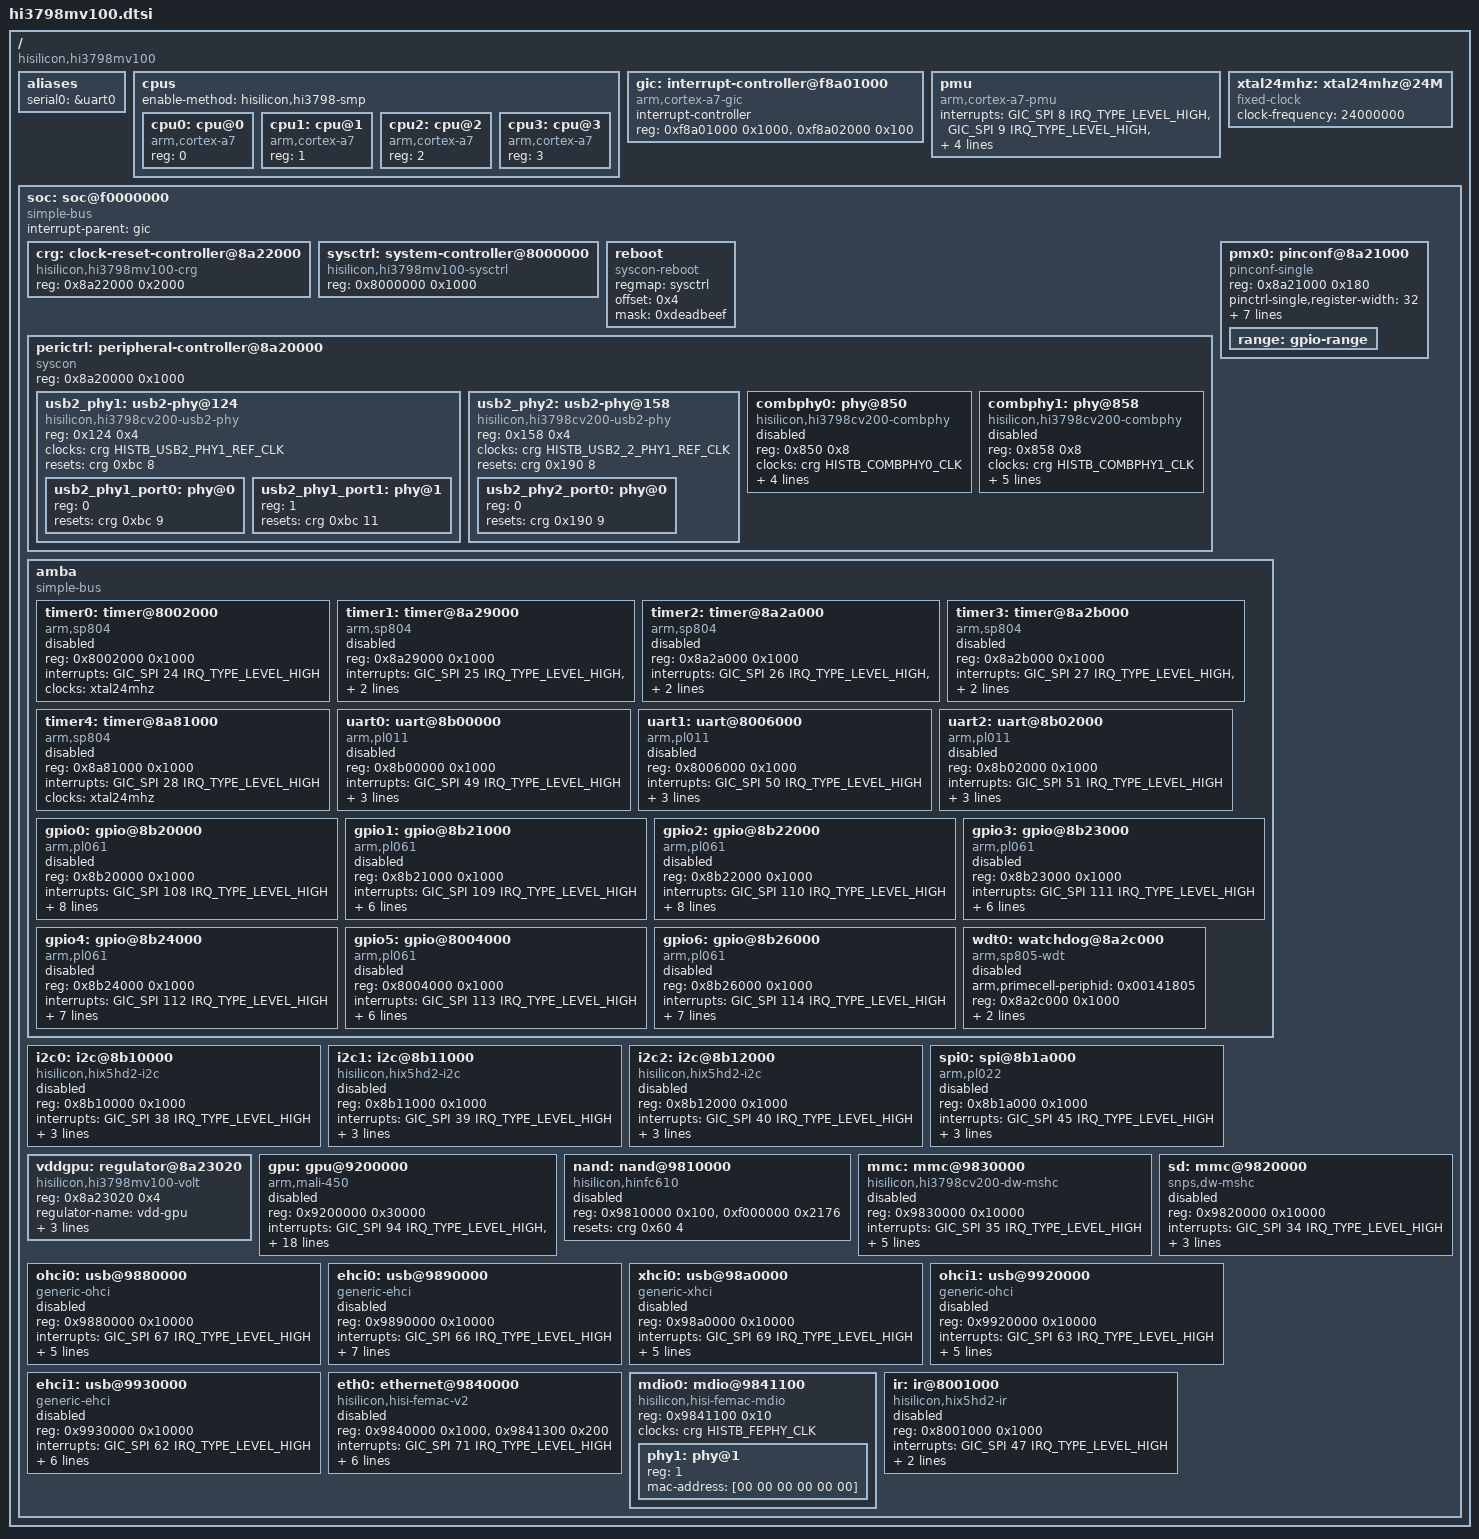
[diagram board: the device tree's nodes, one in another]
// SPDX-License-Identifier: GPL-2.0
/*
 * Based on arch/arm64/boot/dts/hisilicon/hi3798cv200.dtsi
 *
 * Copyright (c) 2016-2017 HiSilicon Technologies Co., Ltd.
 * Copyright (c) 2023 David Yang
 */

#include <dt-bindings/clock/histb-clock.h>
#include <dt-bindings/gpio/gpio.h>
#include <dt-bindings/interrupt-controller/arm-gic.h>
#include <dt-bindings/phy/phy.h>

/ {
	compatible = "hisilicon,hi3798mv100";
	#address-cells = <1>;
	#size-cells = <1>;

	aliases {
		serial0 = &uart0;
	};

	cpus {
		#address-cells = <1>;
		#size-cells = <0>;
		enable-method = "hisilicon,hi3798-smp";

		cpu0: cpu@0 {
			compatible = "arm,cortex-a7";
			device_type = "cpu";
			reg = <0>;
		};

		cpu1: cpu@1 {
			compatible = "arm,cortex-a7";
			device_type = "cpu";
			reg = <1>;
		};

		cpu2: cpu@2 {
			compatible = "arm,cortex-a7";
			device_type = "cpu";
			reg = <2>;
		};

		cpu3: cpu@3 {
			compatible = "arm,cortex-a7";
			device_type = "cpu";
			reg = <3>;
		};
	};

	gic: interrupt-controller@f8a01000 {
		compatible = "arm,cortex-a7-gic";
		#interrupt-cells = <3>;
		#address-cells = <0>;
		interrupt-controller;
		/* gic dist base, gic cpu base */
		reg = <0xf8a01000 0x1000>, <0xf8a02000 0x100>;
	};

	pmu: pmu {
		compatible = "arm,cortex-a7-pmu";
		interrupts = <GIC_SPI 8 IRQ_TYPE_LEVEL_HIGH>,
			<GIC_SPI 9 IRQ_TYPE_LEVEL_HIGH>,
			<GIC_SPI 10 IRQ_TYPE_LEVEL_HIGH>,
			<GIC_SPI 11 IRQ_TYPE_LEVEL_HIGH>;
		interrupt-affinity = <&cpu0>, <&cpu1>, <&cpu2>, <&cpu3>;
		interrupt-parent = <&gic>;
	};

	xtal24mhz: xtal24mhz@24M {
		compatible = "fixed-clock";
		#clock-cells = <0>;
		clock-frequency = <24000000>;
	};

	soc: soc@f0000000 {
		compatible = "simple-bus";
		#address-cells = <1>;
		#size-cells = <1>;
		interrupt-parent = <&gic>;
		ranges = <0 0xf0000000 0x10000000>;

		crg: clock-reset-controller@8a22000 {
			compatible = "hisilicon,hi3798mv100-crg", "hisilicon,cpuctrl", "syscon", "simple-mfd";
			reg = <0x8a22000 0x2000>;
			#clock-cells = <1>;
			#reset-cells = <2>;
		};

		sysctrl: system-controller@8000000 {
			compatible = "hisilicon,hi3798mv100-sysctrl", "syscon";
			reg = <0x8000000 0x1000>;
			#clock-cells = <1>;
			#reset-cells = <2>;
		};

		reboot {
			compatible = "syscon-reboot";
			regmap = <&sysctrl>;
			offset = <0x4>;
			mask = <0xdeadbeef>;
		};

		perictrl: peripheral-controller@8a20000 {
			compatible = "syscon", "simple-mfd";
			reg = <0x8a20000 0x1000>;
			#address-cells = <1>;
			#size-cells = <1>;
			ranges = <0x0 0x8a20000 0x1000>;

			usb2_phy1: usb2-phy@124 {
				compatible = "hisilicon,hi3798cv200-usb2-phy";
				reg = <0x124 0x4>;
				clocks = <&crg HISTB_USB2_PHY1_REF_CLK>;
				resets = <&crg 0xbc 8>;
				status = "okay";

				#address-cells = <1>;
				#size-cells = <0>;

				usb2_phy1_port0: phy@0 {
					reg = <0>;
					#phy-cells = <0>;
					resets = <&crg 0xbc 9>;
				};

				usb2_phy1_port1: phy@1 {
					reg = <1>;
					#phy-cells = <0>;
					resets = <&crg 0xbc 11>;
				};
			};

			usb2_phy2: usb2-phy@158 {
				compatible = "hisilicon,hi3798cv200-usb2-phy";
				reg = <0x158 0x4>;
				clocks = <&crg HISTB_USB2_2_PHY1_REF_CLK>;
				resets = <&crg 0x190 8>;
				status = "okay";

				#address-cells = <1>;
				#size-cells = <0>;

				usb2_phy2_port0: phy@0 {
					reg = <0>;
					#phy-cells = <0>;
					resets = <&crg 0x190 9>;
				};
			};

			combphy0: phy@850 {
				compatible = "hisilicon,hi3798cv200-combphy";
				reg = <0x850 0x8>;
				#phy-cells = <1>;
				clocks = <&crg HISTB_COMBPHY0_CLK>;
				resets = <&crg 0x188 4>;
				assigned-clocks = <&crg HISTB_COMBPHY0_CLK>;
				assigned-clock-rates = <100000000>;
				hisilicon,fixed-mode = <PHY_TYPE_USB3>;
				status = "disabled";
			};

			combphy1: phy@858 {
				compatible = "hisilicon,hi3798cv200-combphy";
				reg = <0x858 0x8>;
				#phy-cells = <1>;
				clocks = <&crg HISTB_COMBPHY1_CLK>;
				resets = <&crg 0x188 12>;
				assigned-clocks = <&crg HISTB_COMBPHY1_CLK>;
				assigned-clock-rates = <100000000>;
				hisilicon,mode-select-bits = <0x0008 11 (0x3 << 11)>;
				status = "disabled";
			};
		};

		pmx0: pinconf@8a21000 {
			compatible = "pinconf-single";
			reg = <0x8a21000 0x180>;
			pinctrl-single,register-width = <32>;
			pinctrl-single,function-mask = <7>;
			pinctrl-single,gpio-range = <&range 8 3 2>, <&range 79 1 0>, <&range 21 4 5>,
								<&range 25 1 5>, <&range 54 1 2>, <&range 55 2 0>,
								<&range 78 1 1>, <&range 31 1 6>, <&range 32 1 1>,
								<&range 57 8 0>, <&range 80 2 0>, <&range 43 1 2>,
								<&range 44 1 0>, <&range 45 4 2>, <&range 82 8 0>;

			range: gpio-range {
				#pinctrl-single,gpio-range-cells = <3>;
			};
		};

		amba {
			#address-cells = <1>;
			#size-cells = <1>;
			compatible = "simple-bus";
			ranges;

			timer0: timer@8002000 {
				/* MCU only. Unavailable for user. */
				compatible = "arm,sp804", "arm,primecell";
				reg = <0x8002000 0x1000>;
				/* timer00 & timer01 */
				interrupts = <GIC_SPI 24 IRQ_TYPE_LEVEL_HIGH>;
				clocks = <&xtal24mhz>;
				clock-names = "apb_pclk";
				status = "disabled";
			};

			timer1: timer@8a29000 {
				/*
				 * Only used in NORMAL state, not available in
				 * SLOW or DOZE state.
				 * The rate is fixed in 24MHz.
				 */
				compatible = "arm,sp804", "arm,primecell";
				reg = <0x8a29000 0x1000>;
				/* timer10 & timer11 */
				interrupts = <GIC_SPI 25 IRQ_TYPE_LEVEL_HIGH>, <GIC_SPI 58 IRQ_TYPE_LEVEL_HIGH>;
				clocks = <&xtal24mhz>;
				clock-names = "apb_pclk";
				status = "disabled";
			};

			timer2: timer@8a2a000 {
				compatible = "arm,sp804", "arm,primecell";
				reg = <0x8a2a000 0x1000>;
				/* timer20 & timer21 */
				interrupts = <GIC_SPI 26 IRQ_TYPE_LEVEL_HIGH>, <GIC_SPI 59 IRQ_TYPE_LEVEL_HIGH>;
				clocks = <&xtal24mhz>;
				clock-names = "apb_pclk";
				status = "disabled";
			};

			timer3: timer@8a2b000 {
				compatible = "arm,sp804", "arm,primecell";
				reg = <0x8a2b000 0x1000>;
				/* timer30 & timer31 */
				interrupts = <GIC_SPI 27 IRQ_TYPE_LEVEL_HIGH>, <GIC_SPI 60 IRQ_TYPE_LEVEL_HIGH>;
				clocks = <&xtal24mhz>;
				clock-names = "apb_pclk";
				status = "disabled";
			};

			timer4: timer@8a81000 {
				compatible = "arm,sp804", "arm,primecell";
				reg = <0x8a81000 0x1000>;
				/* timer40 & timer41 */
				interrupts = <GIC_SPI 28 IRQ_TYPE_LEVEL_HIGH>;
				clocks = <&xtal24mhz>;
				clock-names = "apb_pclk";
				status = "disabled";
			};

			uart0: uart@8b00000 {
				compatible = "arm,pl011", "arm,primecell";
				reg = <0x8b00000 0x1000>;
				interrupts = <GIC_SPI 49 IRQ_TYPE_LEVEL_HIGH>;
				clocks = <&sysctrl HISTB_UART0_CLK>, <&sysctrl HISTB_UART0_CLK>;
				clock-names = "uartclk", "apb_pclk";
				resets = <&sysctrl 0x48 13>;
				reset-names = "reset";
				status = "disabled";
			};

			uart1: uart@8006000 {
				compatible = "arm,pl011", "arm,primecell";
				reg = <0x8006000 0x1000>;
				interrupts = <GIC_SPI 50 IRQ_TYPE_LEVEL_HIGH>;
				clocks = <&crg HISTB_UART1_CLK>, <&crg HISTB_UART1_CLK>;
				clock-names = "uartclk", "apb_pclk";
				resets = <&crg 0x68 1>;
				reset-names = "reset";
				status = "disabled";
			};

			uart2: uart@8b02000 {
				compatible = "arm,pl011", "arm,primecell";
				reg = <0x8b02000 0x1000>;
				interrupts = <GIC_SPI 51 IRQ_TYPE_LEVEL_HIGH>;
				clocks = <&crg HISTB_UART2_CLK>, <&crg HISTB_UART2_CLK>;
				clock-names = "uartclk", "apb_pclk";
				resets = <&crg 0x68 5>;
				reset-names = "reset";
				status = "disabled";
			};

			gpio0: gpio@8b20000 {
				compatible = "arm,pl061", "arm,primecell";
				reg = <0x8b20000 0x1000>;
				interrupts = <GIC_SPI 108 IRQ_TYPE_LEVEL_HIGH>;
				gpio-controller;
				#gpio-cells = <2>;
				ngpios = <8>;
				interrupt-controller;
				#interrupt-cells = <2>;
				clocks = <&crg HISTB_APB_CLK>;
				clock-names = "apb_pclk";
				status = "disabled";
				gpio-line-names = "GPIO0_0", "GPIO0_1", "GPIO0_2", "GPIO0_3", "GPIO0_4", "GPIO0_5", "GPIO0_6", "GPIO0_7";
				gpio-ranges = <&pmx0 2 10 1>, <&pmx0 3 79 1>, <&pmx0 4 21 4>;
			};

			gpio1: gpio@8b21000 {
				compatible = "arm,pl061", "arm,primecell";
				reg = <0x8b21000 0x1000>;
				interrupts = <GIC_SPI 109 IRQ_TYPE_LEVEL_HIGH>;
				gpio-controller;
				#gpio-cells = <2>;
				ngpios = <8>;
				interrupt-controller;
				#interrupt-cells = <2>;
				clocks = <&crg HISTB_APB_CLK>;
				clock-names = "apb_pclk";
				status = "disabled";
				gpio-line-names = "GPIO1_0", "GPIO1_1", "GPIO1_2", "GPIO1_3", "GPIO1_4", "GPIO1_5", "GPIO1_6", "GPIO1_7";
			};

			gpio2: gpio@8b22000 {
				compatible = "arm,pl061", "arm,primecell";
				reg = <0x8b22000 0x1000>;
				interrupts = <GIC_SPI 110 IRQ_TYPE_LEVEL_HIGH>;
				gpio-controller;
				#gpio-cells = <2>;
				ngpios = <8>;
				interrupt-controller;
				#interrupt-cells = <2>;
				clocks = <&crg HISTB_APB_CLK>;
				clock-names = "apb_pclk";
				status = "disabled";
				gpio-line-names = "GPIO2_0", "GPIO2_1", "GPIO2_2", "GPIO2_3", "GPIO2_4", "GPIO2_5", "GPIO2_6", "GPIO2_7";
				gpio-ranges = <&pmx0 0 25 1>, <&pmx0 1 54 1>, <&pmx0 2 55 2>;
			};

			gpio3: gpio@8b23000 {
				compatible = "arm,pl061", "arm,primecell";
				reg = <0x8b23000 0x1000>;
				interrupts = <GIC_SPI 111 IRQ_TYPE_LEVEL_HIGH>;
				gpio-controller;
				#gpio-cells = <2>;
				ngpios = <8>;
				interrupt-controller;
				#interrupt-cells = <2>;
				clocks = <&crg HISTB_APB_CLK>;
				clock-names = "apb_pclk";
				status = "disabled";
				gpio-line-names = "GPIO3_0", "GPIO3_1", "GPIO3_2", "GPIO3_3", "GPIO3_4", "GPIO3_5", "GPIO3_6", "GPIO3_7";
			};

			gpio4: gpio@8b24000 {
				compatible = "arm,pl061", "arm,primecell";
				reg = <0x8b24000 0x1000>;
				interrupts = <GIC_SPI 112 IRQ_TYPE_LEVEL_HIGH>;
				gpio-controller;
				#gpio-cells = <2>;
				ngpios = <8>;
				interrupt-controller;
				#interrupt-cells = <2>;
				clocks = <&crg HISTB_APB_CLK>;
				clock-names = "apb_pclk";
				status = "disabled";
				gpio-line-names = "GPIO4_0", "GPIO4_1", "GPIO4_2", "GPIO4_3", "GPIO4_4", "GPIO4_5", "GPIO4_6", "GPIO4_7";
				gpio-ranges = <&pmx0 0 80 2>;
			};

			gpio5: gpio@8004000 {
				compatible = "arm,pl061", "arm,primecell";
				reg = <0x8004000 0x1000>;
				interrupts = <GIC_SPI 113 IRQ_TYPE_LEVEL_HIGH>;
				gpio-controller;
				#gpio-cells = <2>;
				ngpios = <8>;
				interrupt-controller;
				#interrupt-cells = <2>;
				clocks = <&crg HISTB_APB_CLK>;
				clock-names = "apb_pclk";
				status = "disabled";
				gpio-line-names = "GPIO5_0", "GPIO5_1", "GPIO5_2", "GPIO5_3", "GPIO5_4", "GPIO5_5", "GPIO5_6", "GPIO5_7";
			};

			gpio6: gpio@8b26000 {
				compatible = "arm,pl061", "arm,primecell";
				reg = <0x8b26000 0x1000>;
				interrupts = <GIC_SPI 114 IRQ_TYPE_LEVEL_HIGH>;
				gpio-controller;
				#gpio-cells = <2>;
				ngpios = <8>;
				interrupt-controller;
				#interrupt-cells = <2>;
				clocks = <&crg HISTB_APB_CLK>;
				clock-names = "apb_pclk";
				status = "disabled";
				gpio-line-names = "GPIO6_0", "GPIO6_1", "GPIO6_2", "GPIO6_3", "GPIO6_4", "GPIO6_5", "GPIO6_6", "GPIO6_7";
				gpio-ranges = <&pmx0 0 82 2>;
			};

			wdt0: watchdog@8a2c000 {
				compatible = "arm,sp805-wdt", "arm,primecell";
				arm,primecell-periphid = <0x00141805>;
				reg = <0x8a2c000 0x1000>;
				interrupts = <GIC_SPI 29 IRQ_TYPE_LEVEL_HIGH>;
				clocks = <&crg HISTB_APB_CLK>;
				clock-names = "apb_pclk";
				status = "disabled";
			};
		};

		i2c0: i2c@8b10000 {
			compatible = "hisilicon,hix5hd2-i2c";
			reg = <0x8b10000 0x1000>;
			interrupts = <GIC_SPI 38 IRQ_TYPE_LEVEL_HIGH>;
			clock-frequency = <400000>;
			clocks = <&crg HISTB_I2C0_CLK>;
			resets = <&crg 0x6c 5>;
			reset-names = "reset";
			status = "disabled";
		};

		i2c1: i2c@8b11000 {
			compatible = "hisilicon,hix5hd2-i2c";
			reg = <0x8b11000 0x1000>;
			interrupts = <GIC_SPI 39 IRQ_TYPE_LEVEL_HIGH>;
			clock-frequency = <400000>;
			clocks = <&crg HISTB_I2C1_CLK>;
			resets = <&crg 0x6c 9>;
			reset-names = "reset";
			status = "disabled";
		};

		i2c2: i2c@8b12000 {
			compatible = "hisilicon,hix5hd2-i2c";
			reg = <0x8b12000 0x1000>;
			interrupts = <GIC_SPI 40 IRQ_TYPE_LEVEL_HIGH>;
			clock-frequency = <400000>;
			clocks = <&crg HISTB_I2C2_CLK>;
			resets = <&crg 0x6c 13>;
			reset-names = "reset";
			status = "disabled";
		};

		spi0: spi@8b1a000 {
			compatible = "arm,pl022", "arm,primecell";
			reg = <0x8b1a000 0x1000>;
			interrupts = <GIC_SPI 45 IRQ_TYPE_LEVEL_HIGH>;
			num-cs = <1>;
			clocks = <&crg HISTB_SPI0_CLK>, <&crg HISTB_SPI0_CLK>;
			clock-names = "sspclk", "apb_pclk";
			resets = <&crg 0x70 1>;
			reset-names = "reset";
			status = "disabled";
		};

		vddgpu: regulator@8a23020 {
			compatible = "hisilicon,hi3798mv100-volt";
			reg = <0x8a23020 0x4>;
			reg-names = "base-address";
			regulator-name = "vdd-gpu";
			regulator-min-microvolt = <900000>;
			regulator-max-microvolt = <1320000>;
			regulator-always-on;
		};

		gpu: gpu@9200000 {
			compatible = "arm,mali-450", "arm,mali-utgard";
			reg = <0x9200000 0x30000>;
			interrupts = <GIC_SPI 94 IRQ_TYPE_LEVEL_HIGH>,
				     <GIC_SPI 94 IRQ_TYPE_LEVEL_HIGH>,
				     <GIC_SPI 94 IRQ_TYPE_LEVEL_HIGH>,
				     <GIC_SPI 94 IRQ_TYPE_LEVEL_HIGH>,
				     <GIC_SPI 94 IRQ_TYPE_LEVEL_HIGH>,
				     <GIC_SPI 94 IRQ_TYPE_LEVEL_HIGH>,
				     <GIC_SPI 94 IRQ_TYPE_LEVEL_HIGH>,
				     <GIC_SPI 94 IRQ_TYPE_LEVEL_HIGH>;
			interrupt-names = "gp", "gpmmu", "pp0", "ppmmu0", "pp1",
					  "ppmmu1", "pmu", "pp";
			pmu_domain_config = <0x1 0x2 0x2 0x0 0x0 0x0 0x0 0x0 0x0 0x1 0x2 0x0>;
			pmu_switch_delay = <0x1ff>;

			clocks = <&crg HISTB_GPU_BUS_CLK>, <&crg HISTB_GPU_GP_CLK>;
			clock-names = "bus", "core";
			resets = <&crg 0xd4 4>;
			status = "disabled";

			mali-supply = <&vddgpu>;
			operating-points = <150000 000000
					    200000 000000
					    250000 000000
					    300000 000000
					    345600 000000
					    400000 000000
					    432000 000000
					    500000 000000>;
			cooling-min-state = <0>;
			cooling-max-state = <7>;
			#cooling-cells = <2>; /* min followed by max */
		};

		nand: nand@9810000 {
			compatible = "hisilicon,hinfc610";
			reg = <0x9810000 0x100>, <0xf000000 0x2176>;
			/* clocks = <&crg HISTB_NAND_CLK>; */
			clock-names = "apb_pclk";
			resets = <&crg 0x60 4>;
			reset-names = "reset";
			status = "disabled";
		};

		/* unremovable emmc as mmcblk0 */
		mmc: mmc@9830000 {
			compatible = "hisilicon,hi3798cv200-dw-mshc";
			reg = <0x9830000 0x10000>;
			interrupts = <GIC_SPI 35 IRQ_TYPE_LEVEL_HIGH>;
			clocks = <&crg HISTB_MMC_CIU_CLK>,
				 <&crg HISTB_MMC_BIU_CLK>,
				 <&crg HISTB_MMC_SAMPLE_CLK>,
				 <&crg HISTB_MMC_DRV_CLK>;
			clock-names = "ciu", "biu", "ciu-sample", "ciu-drive";
			resets = <&crg 0xa0 4>;
			reset-names = "reset";
			status = "disabled";
		};

		sd: mmc@9820000 {
			compatible = "snps,dw-mshc";
			reg = <0x9820000 0x10000>;
			interrupts = <GIC_SPI 34 IRQ_TYPE_LEVEL_HIGH>;
			clocks = <&crg HISTB_SDIO0_CIU_CLK>,
				 <&crg HISTB_SDIO0_BIU_CLK>;
			clock-names = "ciu", "biu";
			resets = <&crg 0x9c 4>;
			reset-names = "reset";
			status = "disabled";
		};

		ohci0: usb@9880000 {
			compatible = "generic-ohci";
			reg = <0x9880000 0x10000>;
			interrupts = <GIC_SPI 67 IRQ_TYPE_LEVEL_HIGH>;
			clocks = <&crg HISTB_USB2_BUS_CLK>,
				 <&crg HISTB_USB2_12M_CLK>,
				 <&crg HISTB_USB2_48M_CLK>;
			clock-names = "bus", "clk12", "clk48";
			resets = <&crg 0xb8 12>;
			reset-names = "bus";
			phys = <&usb2_phy1_port0>, <&usb2_phy1_port1>;
			phy-names = "usb0", "usb1";
			status = "disabled";
		};

		ehci0: usb@9890000 {
			compatible = "generic-ehci";
			reg = <0x9890000 0x10000>;
			interrupts = <GIC_SPI 66 IRQ_TYPE_LEVEL_HIGH>;
			clocks = <&crg HISTB_USB2_BUS_CLK>,
				 <&crg HISTB_USB2_PHY_CLK>,
				 <&crg HISTB_USB2_UTMI_CLK>,
				 <&crg HISTB_USB2_UTMI_CLK1>;
			clock-names = "bus", "phy", "utmi0", "utmi1";
			resets = <&crg 0xb8 12>,
				 <&crg 0xb8 16>,
				 <&crg 0xb8 13>,
				 <&crg 0xb8 14>;
			reset-names = "bus", "phy", "utmi0", "utmi1";
			phys = <&usb2_phy1_port0>, <&usb2_phy1_port1>;
			phy-names = "usb0", "usb1";
			status = "disabled";
		};

		xhci0: usb@98a0000 {
			compatible = "generic-xhci";
			reg = <0x98a0000 0x10000>;
			interrupts = <GIC_SPI 69 IRQ_TYPE_LEVEL_HIGH>;
			clocks = <&crg HISTB_USB3_BUS_CLK>,
				 <&crg HISTB_USB3_UTMI_CLK>,
				 <&crg HISTB_USB3_PIPE_CLK>,
				 <&crg HISTB_USB3_SUSPEND_CLK>;
			clock-names = "bus", "utmi0", "pipe", "suspend";
			resets = <&crg 0xb0 12>;
			reset-names = "vcc";
			status = "disabled";
		};

		ohci1: usb@9920000 {
			compatible = "generic-ohci";
			reg = <0x9920000 0x10000>;
			interrupts = <GIC_SPI 63 IRQ_TYPE_LEVEL_HIGH>;
			clocks = <&crg HISTB_USB2_2_BUS_CLK>,
				 <&crg HISTB_USB2_2_12M_CLK>,
				 <&crg HISTB_USB2_2_48M_CLK>;
			clock-names = "bus", "clk12", "clk48";
			resets = <&crg 0x198 12>;
			reset-names = "bus";
			phys = <&usb2_phy2_port0>;
			phy-names = "usb";
			status = "disabled";
		};

		ehci1: usb@9930000 {
			compatible = "generic-ehci";
			reg = <0x9930000 0x10000>;
			interrupts = <GIC_SPI 62 IRQ_TYPE_LEVEL_HIGH>;
			clocks = <&crg HISTB_USB2_2_BUS_CLK>,
				 <&crg HISTB_USB2_2_PHY_CLK>,
				 <&crg HISTB_USB2_2_UTMI_CLK>;
			clock-names = "bus", "phy", "utmi";
			resets = <&crg 0x198 12>,
				 <&crg 0x198 16>,
				 <&crg 0x198 14>;
			reset-names = "bus", "phy", "utmi";
			phys = <&usb2_phy2_port0>;
			phy-names = "usb";
			status = "disabled";
		};
		eth0: ethernet@9840000 {
			compatible = "hisilicon,hisi-femac-v2";
			reg = <0x9840000 0x1000>, <0x9841300 0x200>;
			interrupts = <GIC_SPI 71 IRQ_TYPE_LEVEL_HIGH>;
			clocks = <&crg HISTB_ETH0_MAC_CLK>;
			resets = <&crg 0xcc 4>, <&crg 0x120 4>;
			reset-names = "mac", "phy";
			status = "disabled";

			phy-handle = <&phy1>;
			phy-mode = "mii";
			hisilicon,phy-reset-delays-us = <10000 10000 20000>;
		};

		mdio0: mdio@9841100 {
			compatible = "hisilicon,hisi-femac-mdio";
			reg = <0x9841100 0x10>;
			clocks = <&crg HISTB_FEPHY_CLK>;

			#address-cells = <1>;
			#size-cells = <0>;

			phy1: phy@1 {
				reg = <1>;
				/* Placeholder, overwritten by bootloader */
				mac-address = [00 00 00 00 00 00];
			};
		};

		ir: ir@8001000 {
			compatible = "hisilicon,hix5hd2-ir";
			reg = <0x8001000 0x1000>;
			interrupts = <GIC_SPI 47 IRQ_TYPE_LEVEL_HIGH>;
			clocks = <&sysctrl HISTB_IR_CLK>;
			clock-names = "apb_pclk";
			resets = <&sysctrl 0x48 5>;
			reset-names = "reset";
			status = "disabled";
		};
	};
};
